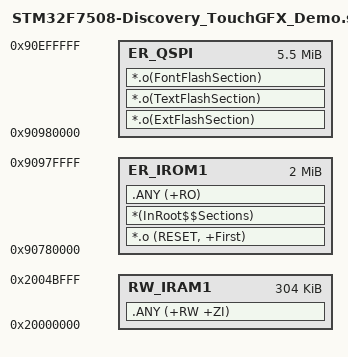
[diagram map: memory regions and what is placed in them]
; *************************************************************
; *** Scatter-Loading Description File generated by uVision ***
; *************************************************************

LR_IROM1 0x90780000 0x00200000  {    ; load region size_region
  ER_IROM1 0x90780000 0x00200000  {  ; load address = execution address
   *.o (RESET, +First)
   *(InRoot$$Sections)
   .ANY (+RO)
  }
  RW_IRAM1 0x20000000 0x0004C000  {  ; RW data
   .ANY (+RW +ZI)
  }
}

   LR_QSPI 0x90980000 0x00580000  {
   ER_QSPI 0x90980000 0x00580000 {
	*.o(ExtFlashSection)
	*.o(TextFlashSection)
	*.o(FontFlashSection)          	
  }
}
